VERSION ""

NS_ :

BS_:

BU_:

BO_ 3221225472 VECTOR__INDEPENDENT_SIG_MSG: 0 Vector__XXX
 SG_ MultiTurn : 0|16@1+ (1,0) [0|65535] "rot" Vector__XXX

BO_ 2566848522 SteerEncoder: 5 Vector__XXX
 SG_ Error : 32|8@1+ (1,0) [0|255] "" Vector__XXX
 SG_ SingleTurn : 0|32@1- (1,0) [0|65535] "pls" Vector__XXX

BO_ 2565799936 SteerEncStart: 8 Vector__XXX
 SG_ StartValue : 0|64@1+ (1,0) [0|65281] "_" Vector__XXX

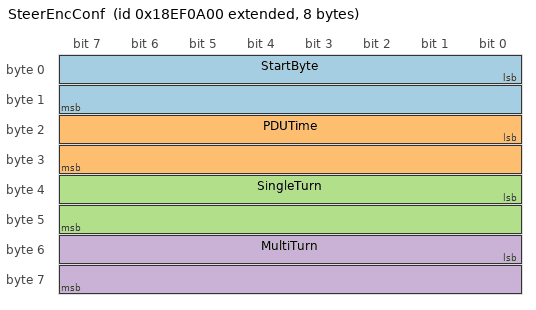
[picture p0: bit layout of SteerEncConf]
BO_ 2565802496 SteerEncConf: 8 Vector__XXX
 SG_ StartByte : 0|16@1+ (1,0) [0|65281] "_" Vector__XXX
 SG_ PDUTime : 16|16@1+ (1,0) [0|65535] "" Vector__XXX
 SG_ SingleTurn : 32|16@1+ (1,0) [0|65535] "pls" Vector__XXX
 SG_ MultiTurn : 48|16@1+ (1,0) [0|65535] "rot" Vector__XXX

CM_ BO_ 3221225472 "This is a message for not used signals, created by Vector CANdb++ DBC OLE DB Provider.";
BA_DEF_  "BusType" STRING ;
BA_DEF_DEF_  "BusType" "";
BA_ "BusType" "CAN";
